# STM32C031 register map
File version: 1.4
CPU: CM0 r0p0, little endian, MPU, FPU, 2 interrupt priority bits
Registers are 32-bit, read-write, reset 0x0 unless marked. A register's access mark holds for its fields unless they carry their own. Offsets are from the block's base; [hi:lo] are bit positions; {n}, {i} and the like mark numbered series.

## SYSCFG — SYSCFG register block
Base 0x40010000
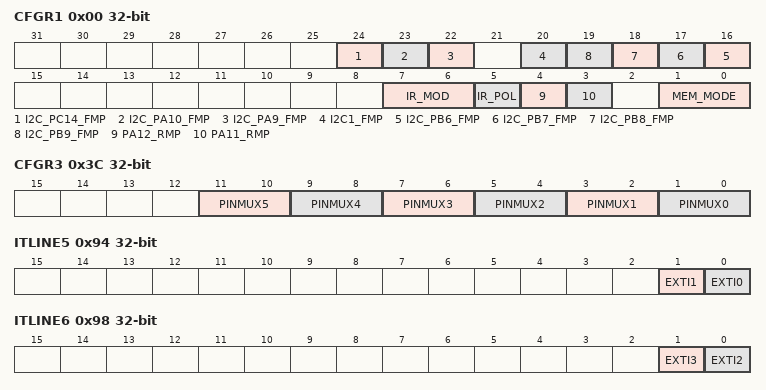
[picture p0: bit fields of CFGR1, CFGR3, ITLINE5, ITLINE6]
0x00 CFGR1 (reset mask 0xFFFFFFF0) — SYSCFG configuration register 1
  [24] I2C_PC14_FMP — Fast Mode Plus (FM+) enable for PC14 This bit is set and cleared by software. It enables I2C FM+ driving capability on PC14 I/O port. With this bit in disable state, the I2C FM+ driving capability on this I/O port can be enabled through one of I2Cx_FMP bits. When I2C FM+ is enabled, the speed control is ignored.
  [23] I2C_PA10_FMP — Fast Mode Plus (FM+) enable for PA10 This bit is set and cleared by software. It enables I2C FM+ driving capability on PA10 I/O port. With this bit in disable state, the I2C FM+ driving capability on this I/O port can be enabled through one of I2Cx_FMP bits. When I2C FM+ is enabled, the speed control is ignored.
  [22] I2C_PA9_FMP — Fast Mode Plus (FM+) enable for PA9 This bit is set and cleared by software. It enables I2C FM+ driving capability on PA9 I/O port. With this bit in disable state, the I2C FM+ driving capability on this I/O port can be enabled through one of I2Cx_FMP bits. When I2C FM+ is enabled, the speed control is ignored.
  [20] I2C1_FMP — Fast Mode Plus (FM+) enable for I2C1 This bit is set and cleared by software. It enables I2C FM+ driving capability on I/O ports configured as I2C1 through GPIOx_AFR registers. With this bit in disable state, the I2C FM+ driving capability on I/O ports configured as I2C1 can be enabled through their corresponding I2Cx_FMP bit. When I2C FM+ is enabled, the speed control is ignored.
  [n+10] I2C_PB{n}_FMP (n=6..9) — Fast Mode Plus (FM+) enable for PB{n} This bit is set and cleared by software. It enables I2C FM+ driving capability on PB{n} I/O port. With this bit in disable state, the I2C FM+ driving capability on this I/O port can be enabled through one of I2Cx_FMP bits. When I2C FM+ is enabled, the speed control is ignored.
  [7:6] IR_MOD — IR Modulation Envelope signal selection This bitfield selects the signal for IR modulation envelope:
  [5] IR_POL — IR output polarity selection
  [4] PA12_RMP — PA12 pin remapping This bit is set and cleared by software. When set, it remaps the PA12 pin to operate as PA10 GPIO port, instead as PA12 GPIO port.
  [3] PA11_RMP — PA11 pin remapping This bit is set and cleared by software. When set, it remaps the PA11 pin to operate as PA9 GPIO port, instead as PA11 GPIO port.
  [1:0] MEM_MODE — Memory mapping selection bits This bitfield controlled by software selects the memory internally mapped at the address 0x0000 0000. Its reset value is determined by the boot mode configuration. Refer to for more details. x0: Main Flash memory
0x18 CFGR2 — SYSCFG configuration register 2
  [0] LOCKUP_LOCK — Cortex<Superscript><Default Font>-M0+ LOCKUP enable This bit is set by software and cleared by system reset. When set, it enables the connection of Cortex<Superscript><Default Font>-M0+ LOCKUP (HardFault) output to the TIM1/16/17 Break input.
0x3C CFGR3 — SYSCFG configuration register 3
  [11:10] PINMUX5 — Pin GPIO multiplexer 5 This bit is set by software and cleared by system reset. It assigns a GPIO to a pin. 1x: Reserved
  [9:8] PINMUX4 — Pin GPIO multiplexer 4 This bit is set by software and cleared by system reset. It assigns a GPIO to a pin. 1x: Reserved 1x: Reserved
  [7:6] PINMUX3 — Pin GPIO multiplexer 3 This bit is set by software and cleared by system reset. It assigns a GPIO to a pin. 1x: Reserved
  [5:4] PINMUX2 — Pin GPIO multiplexer 2 This bit is set by software and cleared by system reset. It assigns a GPIO to a pin. 1x: Reserved 1x: Reserved
  [3:2] PINMUX1 — Pin GPIO multiplexer 1 This bit is set by software and cleared by system reset. It assigns a GPIO to a pin. 1x: Reserved
  [1:0] PINMUX0 — Pin GPIO multiplexer 0 This bit is set by software and cleared by system reset. It assigns a GPIO to a pin. 1x: Reserved Pin F2 of WLCSP14 package GPIO assignment 1x: Reserved
0x80 ITLINE0 ro — SYSCFG interrupt line 0 status register
  [0] WWDG — Window watchdog interrupt pending flag
0x88 ITLINE2 ro — SYSCFG interrupt line 2 status register
  [1] RTC — RTC interrupt request pending (EXTI line 19)
0x8C ITLINE3 ro — SYSCFG interrupt line 3 status register
  [1] FLASH_ITF — Flash interface interrupt request pending
0x90 ITLINE4 ro — SYSCFG interrupt line 4 status register
  [0] RCC — Reset and clock control interrupt request pending
0x94 ITLINE5 ro — SYSCFG interrupt line 5 status register
  [1] EXTI1 — EXTI line 1 interrupt request pending
  [0] EXTI0 — EXTI line 0 interrupt request pending
0x98 ITLINE6 ro — SYSCFG interrupt line 6 status register
  [1] EXTI3 — EXTI line 3 interrupt request pending
  [0] EXTI2 — EXTI line 2 interrupt request pending
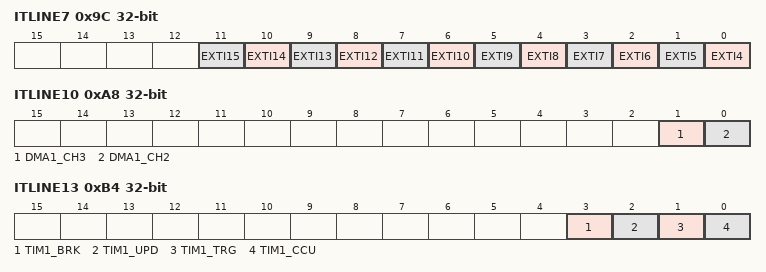
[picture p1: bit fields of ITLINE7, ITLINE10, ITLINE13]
0x9C ITLINE7 ro — SYSCFG interrupt line 7 status register
  [n-4] EXTI{n} (n=4..15) — EXTI line {n} interrupt request pending
0xA4 ITLINE9 ro — SYSCFG interrupt line 9 status register
  [0] DMA1_CH1 — DMA1 channel 1interrupt request pending
0xA8 ITLINE10 ro — SYSCFG interrupt line 10 status register
  [1] DMA1_CH3 — DMA1 channel 3 interrupt request pending
  [0] DMA1_CH2 — DMA1 channel 2 interrupt request pending
0xAC ITLINE11 ro — SYSCFG interrupt line 11 status register
  [0] DMAMUX — DMAMUX interrupt request pending
0xB0 ITLINE12 ro — SYSCFG interrupt line 12 status register
  [0] ADC — ADC interrupt request pending
0xB4 ITLINE13 ro — SYSCFG interrupt line 13 status register
  [3] TIM1_BRK — Timer 1 break interrupt request pending
  [2] TIM1_UPD — Timer 1 update interrupt request pending
  [1] TIM1_TRG — Timer 1 trigger interrupt request pending
  [0] TIM1_CCU — Timer 1 commutation interrupt request pending
0xB8 ITLINE14 ro — SYSCFG interrupt line 14 status register
  [0] TIM1_CC — Timer 1 capture compare interrupt request pending
0xC0 ITLINE16 ro — SYSCFG interrupt line 16 status register
  [0] TIM3 — Timer 3 interrupt request pending
0xCC ITLINE19 ro — SYSCFG interrupt line 19 status register
  [0] TIM14 — Timer 14 interrupt request pending
0xD4 ITLINE21 ro — SYSCFG interrupt line 21 status register
  [0] TIM16 — Timer 16 interrupt request pending
0xD8 ITLINE22 ro — SYSCFG interrupt line 22 status register
  [0] TIM17 — Timer 17 interrupt request pending
0xDC ITLINE23 ro — SYSCFG interrupt line 23 status register
  [0] I2C1 — I2C1 interrupt request pending, combined with EXTI line 23
0xE4 ITLINE25 ro — SYSCFG interrupt line 25 status register
  [0] SPI1 — SPI1 interrupt request pending
0xEC ITLINE27 ro — SYSCFG interrupt line 27 status register
  [0] USART1 — USART1 interrupt request pending, combined with EXTI line 25
0xF0 ITLINE28 ro — SYSCFG interrupt line 28 status register
  [0] USART2 — USART2 interrupt request pending (EXTI line 26)
